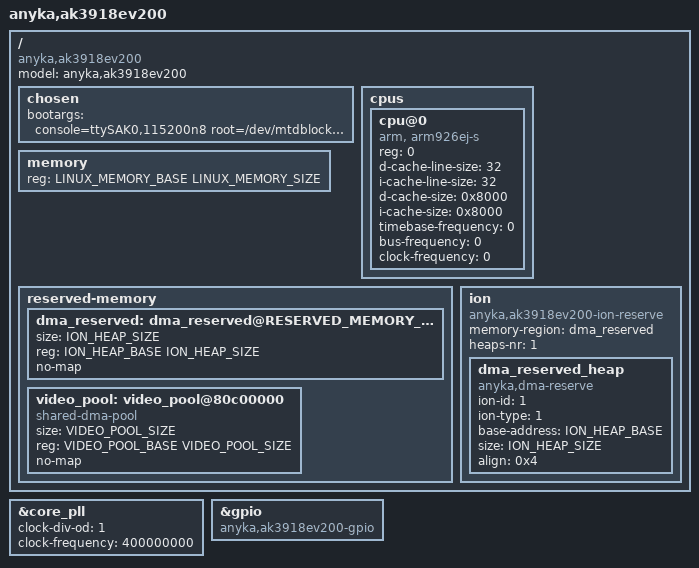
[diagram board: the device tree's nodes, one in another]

#include "anycloud_ak39ev330_common.dtsi"

#define RESERVED_MEMORY_BASE  0x80000000
#define RESERVED_MEMORY_SIZE  0x1800000

#define ION_HEAP_BASE         RESERVED_MEMORY_BASE
#define ION_HEAP_SIZE         0xc00000

#define VIDEO_POOL_BASE       (RESERVED_MEMORY_BASE + ION_HEAP_SIZE)
#define VIDEO_POOL_SIZE       (RESERVED_MEMORY_SIZE - ION_HEAP_SIZE)

#define LINUX_MEMORY_BASE     (RESERVED_MEMORY_BASE + RESERVED_MEMORY_SIZE)
#define LINUX_MEMORY_SIZE     (0x04000000 - RESERVED_MEMORY_SIZE)

/ {
    model = "anyka,ak3918ev200";
    compatible = "anyka,ak3918ev200";

	chosen {
		bootargs = "console=ttySAK0,115200n8 root=/dev/mtdblock4 rootfstype=squashfs init=/sbin/akcam-preinit akcam.jffs=/dev/mtdblock5 mem=64M memsize=64M";
	};

	cpus {
	    #address-cells = <1>;
	    #size-cells = <0>;

	    cpu@0 {
	        compatible = "arm, arm926ej-s";
	        device_type = "cpu";
	        reg = <0>;
	        d-cache-line-size = <32>;
	        i-cache-line-size = <32>;
	        d-cache-size = <0x8000>;
	        i-cache-size = <0x8000>;
	        timebase-frequency = <0>;
	        bus-frequency = <0>;
	        clock-frequency = <0>;
	    };
	};

    memory {
	    device_type = "memory";
	    reg = <LINUX_MEMORY_BASE LINUX_MEMORY_SIZE>;
	};

    reserved-memory {
        #address-cells = <1>;
        #size-cells = <1>;
        ranges;

        dma_reserved: dma_reserved@RESERVED_MEMORY_BASE {
            size = <ION_HEAP_SIZE>;
            reg = <ION_HEAP_BASE ION_HEAP_SIZE>;
            no-map;
            status = "okay";
        };

        video_pool: video_pool@80c00000 {
            compatible = "shared-dma-pool";
            size = <VIDEO_POOL_SIZE>;
            reg = <VIDEO_POOL_BASE VIDEO_POOL_SIZE>;
            no-map;
            status = "okay";
        };
    };

    ion {
        compatible = "anyka,ak3918ev200-ion-reserve";
        memory-region = <&dma_reserved>;
        #address-cells = <1>;
        #size-cells = <1>;
        heaps-nr = <1>;
        ranges;

        dma_reserved_heap: dma_reserved_heap {
            compatible = "anyka,dma-reserve";
            ion-id = <1>;
            ion-type = <1>;
            base-address = <ION_HEAP_BASE>;
            size = <ION_HEAP_SIZE>;
            align = <0x4>;
            status = "okay";
        };
    };
};

&core_pll {
    clock-div-od = <1>;
    clock-frequency = <400000000>;
};

&gpio {
    compatible = "anyka,ak3918ev200-gpio";
};
